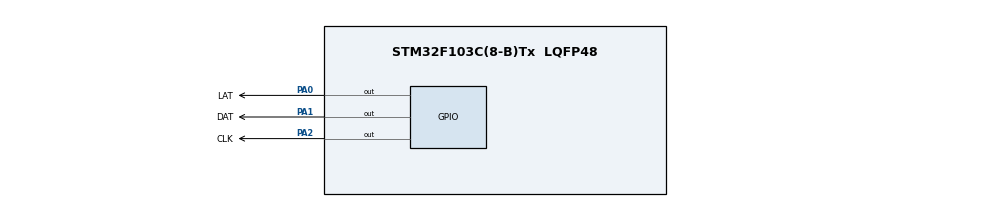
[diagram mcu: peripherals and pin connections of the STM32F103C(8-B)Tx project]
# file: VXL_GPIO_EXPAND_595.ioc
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Mcu.Family=STM32F1
Mcu.Name=STM32F103C(8-B)Tx
Mcu.Package=LQFP48
NVIC.PriorityGroup=NVIC_PRIORITYGROUP_4
PA0-WKUP.GPIO_Label=LAT
PA0-WKUP.Signal=GPIO_Output
PA1.GPIO_Label=DAT
PA1.Signal=GPIO_Output
PA13.Mode=Serial_Wire
PA13.Signal=SYS_JTMS-SWDIO
PA14.Mode=Serial_Wire
PA14.Signal=SYS_JTCK-SWCLK
PA2.GPIO_Label=CLK
PA2.Signal=GPIO_Output
ProjectManager.HeapSize=0x200
ProjectManager.StackSize=0x400
ProjectManager.TargetToolchain=MDK-ARM V5.27
RCC.APB1Freq_Value=8000000
RCC.APB2Freq_Value=8000000
board=custom

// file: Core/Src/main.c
/* USER CODE BEGIN Header */
/**
  ******************************************************************************
  * @file           : main.c
  * @brief          : Main program body
  ******************************************************************************
  * @attention
  *
  * Copyright (c) 2023 STMicroelectronics.
  * All rights reserved.
  *
  * This software is licensed under terms that can be found in the LICENSE file
  * in the root directory of this software component.
  * If no LICENSE file comes with this software, it is provided AS-IS.
  *
  ******************************************************************************
  */
/* USER CODE END Header */
#include "main.h"

/* USER CODE BEGIN PV */
const uint8_t LED[] = {0xFC,0x60,0xDA,0xF2,0x66,0xB6,0xBE,0xE0,0xFE,0xF6,0x00};
/* USER CODE END PV */

void SystemClock_Config(void);
static void MX_GPIO_Init(void);

/* USER CODE BEGIN 0 */
// xung clock
void LED_CLK(uint32_t n){
	while(n>0){
		HAL_GPIO_WritePin(CLK_GPIO_Port,CLK_Pin,1);
		HAL_GPIO_WritePin(CLK_GPIO_Port,CLK_Pin,0);
		n = n-1;
	}
}

// day tung so len led, day 8 lan
void LED_push(uint8_t n){
	for(uint8_t i = 0; i<8; i++){
		HAL_GPIO_WritePin(DAT_GPIO_Port,DAT_Pin,LED[n]>>i&1u);
		LED_CLK(1);
	}
}
// truy cap gia tri tai tung vi tr? cua so n, bat dau tu hang don vi. Sau do dung ham LED_push day so len led lan luot. Co kiem tra so 0 dung dau
void LED_print(uint32_t n){
	LED_push(n%10);
	HAL_GPIO_WritePin(DAT_GPIO_Port,DAT_Pin,0);
	LED_CLK(1);
	LED_push((n/10)%10);
}
/* USER CODE END 0 */

int main(void)
{

  /* MCU Configuration--------------------------------------------------------*/

  /* Reset of all peripherals, Initializes the Flash interface and the Systick. */
  HAL_Init();

  /* Configure the system clock */
  SystemClock_Config();

  /* Initialize all configured peripherals */
  MX_GPIO_Init();

  /* Infinite loop */
  while (1)
  {
		for (uint32_t i = 0; i <100; i++) {
			LED_print(i);
			HAL_GPIO_WritePin(LAT_GPIO_Port,LAT_Pin,1);
			HAL_GPIO_WritePin(LAT_GPIO_Port,LAT_Pin,0);
			HAL_Delay(200);
		}
  }
}

void SystemClock_Config(void)
{
  RCC_OscInitTypeDef RCC_OscInitStruct = {0};
  RCC_ClkInitTypeDef RCC_ClkInitStruct = {0};

  /** Initializes the RCC Oscillators according to the specified parameters
  * in the RCC_OscInitTypeDef structure.
  */
  RCC_OscInitStruct.OscillatorType = RCC_OSCILLATORTYPE_HSI;
  RCC_OscInitStruct.HSIState = RCC_HSI_ON;
  RCC_OscInitStruct.HSICalibrationValue = RCC_HSICALIBRATION_DEFAULT;
  RCC_OscInitStruct.PLL.PLLState = RCC_PLL_NONE;
  if (HAL_RCC_OscConfig(&RCC_OscInitStruct) != HAL_OK)
  {
    Error_Handler();
  }

  /** Initializes the CPU, AHB and APB buses clocks
  */
  RCC_ClkInitStruct.ClockType = RCC_CLOCKTYPE_HCLK|RCC_CLOCKTYPE_SYSCLK
                              |RCC_CLOCKTYPE_PCLK1|RCC_CLOCKTYPE_PCLK2;
  RCC_ClkInitStruct.SYSCLKSource = RCC_SYSCLKSOURCE_HSI;
  RCC_ClkInitStruct.AHBCLKDivider = RCC_SYSCLK_DIV1;
  RCC_ClkInitStruct.APB1CLKDivider = RCC_HCLK_DIV1;
  RCC_ClkInitStruct.APB2CLKDivider = RCC_HCLK_DIV1;

  if (HAL_RCC_ClockConfig(&RCC_ClkInitStruct, FLASH_LATENCY_0) != HAL_OK)
  {
    Error_Handler();
  }
}

static void MX_GPIO_Init(void)
{
  GPIO_InitTypeDef GPIO_InitStruct = {0};

  /* GPIO Ports Clock Enable */
  __HAL_RCC_GPIOA_CLK_ENABLE();

  /*Configure GPIO pin Output Level */
  HAL_GPIO_WritePin(GPIOA, LAT_Pin|DAT_Pin|CLK_Pin, GPIO_PIN_RESET);

  /*Configure GPIO pins : LAT_Pin DAT_Pin CLK_Pin */
  GPIO_InitStruct.Pin = LAT_Pin|DAT_Pin|CLK_Pin;
  GPIO_InitStruct.Mode = GPIO_MODE_OUTPUT_PP;
  GPIO_InitStruct.Pull = GPIO_NOPULL;
  GPIO_InitStruct.Speed = GPIO_SPEED_FREQ_LOW;
  HAL_GPIO_Init(GPIOA, &GPIO_InitStruct);

}

void Error_Handler(void)
{
  __disable_irq();
  while (1)
  {
  }
}
